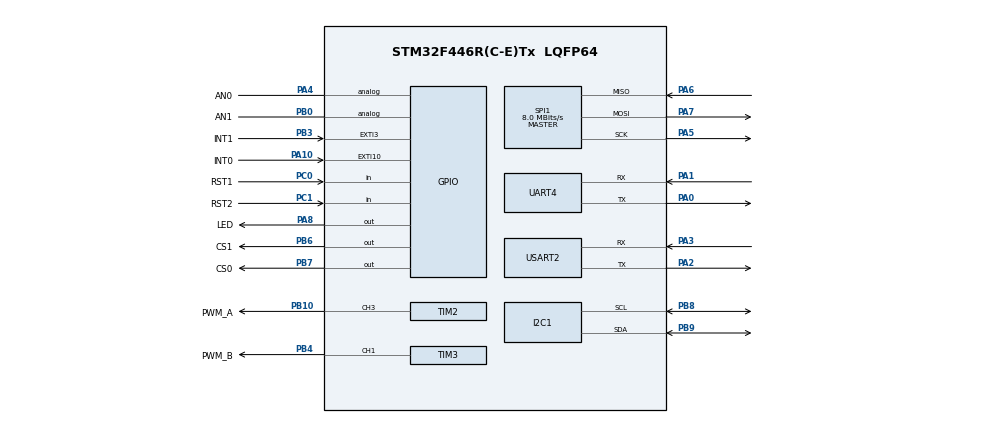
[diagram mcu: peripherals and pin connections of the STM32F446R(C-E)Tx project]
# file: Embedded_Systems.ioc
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Mcu.Family=STM32F4
Mcu.Name=STM32F446R(C-E)Tx
Mcu.Package=LQFP64
NVIC.I2C1_ER_IRQn=true\:0\:0\:false\:false\:true\:true\:true\:true
NVIC.I2C1_EV_IRQn=true\:0\:0\:false\:false\:true\:true\:true\:true
NVIC.PriorityGroup=NVIC_PRIORITYGROUP_4
NVIC.SPI1_IRQn=true\:0\:0\:false\:false\:true\:true\:true\:true
NVIC.UART4_IRQn=true\:0\:0\:false\:false\:true\:true\:true\:true
NVIC.USART2_IRQn=true\:0\:0\:false\:false\:true\:true\:true\:true
PA0-WKUP.Mode=Asynchronous
PA0-WKUP.Signal=UART4_TX
PA1.Mode=Asynchronous
PA1.Signal=UART4_RX
PA10.GPIO_Label=INT0
PA10.Signal=GPXTI10
PA2.Mode=Asynchronous
PA2.Signal=USART2_TX
PA3.Mode=Asynchronous
PA3.Signal=USART2_RX
PA4.GPIO_Label=AN0
PA4.Signal=GPIO_Analog
PA5.Mode=Full_Duplex_Master
PA5.Signal=SPI1_SCK
PA6.Mode=Full_Duplex_Master
PA6.Signal=SPI1_MISO
PA7.Mode=Full_Duplex_Master
PA7.Signal=SPI1_MOSI
PA8.GPIO_Label=LED
PA8.Signal=GPIO_Output
PB0.GPIO_Label=AN1
PB0.Signal=GPIO_Analog
PB10.GPIO_Label=PWM_A
PB10.Signal=S_TIM2_CH3
PB3.GPIO_Label=INT1
PB3.Signal=GPXTI3
PB4.GPIO_Label=PWM_B
PB4.Signal=S_TIM3_CH1
PB6.GPIO_Label=CS1
PB6.Signal=GPIO_Output
PB7.GPIO_Label=CS0
PB7.Signal=GPIO_Output
PB8.Mode=I2C
PB8.Signal=I2C1_SCL
PB9.Mode=I2C
PB9.Signal=I2C1_SDA
PC0.GPIO_Label=RST1
PC0.Signal=GPIO_Input
PC1.GPIO_Label=RST2
PC1.Signal=GPIO_Input
ProjectManager.HeapSize=0x200
ProjectManager.StackSize=0x400
ProjectManager.TargetToolchain=STM32CubeIDE
RCC.CortexFreq_Value=16000000
RCC.USBFreq_Value=96000000
RCC.VCOOutputFreq_Value=192000000
SH.S_TIM2_CH3.0=TIM2_CH3,PWM Generation3 CH3
SH.S_TIM3_CH1.0=TIM3_CH1,PWM Generation1 CH1
SPI1.CalculateBaudRate=8.0 MBits/s
SPI1.Direction=SPI_DIRECTION_2LINES
SPI1.Mode=SPI_MODE_MASTER
SPI1.VirtualType=VM_MASTER
TIM2.Channel-PWM\ Generation3\ CH3=TIM_CHANNEL_3
TIM3.Channel-PWM\ Generation1\ CH1=TIM_CHANNEL_1
UART4.VirtualMode=Asynchronous
USART2.VirtualMode=VM_ASYNC
board=custom

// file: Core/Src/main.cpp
/* USER CODE BEGIN Header */
/**
  ******************************************************************************
  * @file           : main.c
  * @brief          : Main program body
  ******************************************************************************
  * @attention
  *
  * Copyright (c) 2023 STMicroelectronics.
  * All rights reserved.
  *
  * This software is licensed under terms that can be found in the LICENSE file
  * in the root directory of this software component.
  * If no LICENSE file comes with this software, it is provided AS-IS.
  *
  ******************************************************************************
  */
/* USER CODE END Header */
#include "main.h"

I2C_HandleTypeDef hi2c1;

SPI_HandleTypeDef hspi1;

TIM_HandleTypeDef htim2;
TIM_HandleTypeDef htim3;

UART_HandleTypeDef huart4;

UART_HandleTypeDef huart2;

void SystemClock_Config(void);

static void MX_GPIO_Init(void);

static void MX_I2C1_Init(void);

static void MX_SPI1_Init(void);

static void MX_TIM2_Init(void);

static void MX_TIM3_Init(void);

static void MX_UART4_Init(void);

static void MX_USART2_UART_Init(void);

/* USER CODE BEGIN 0 */

// TODO 1
/**
 * Set the GPIO value to different values for an LED to turn on and off.
 *
 * The GPIO functionality for you to use can be found on line 233 of this file
 * EmbeddedSystems/Drivers/STM32F4xx_HAL_Driver/Inc/stm32f4xx_hal_gpio.h
 *
 *
 * NOTE: If you believe it to be stuck to on, realize that the device is running faster for you to process
 * You can use the HAL_Delay() function to delay the program for a certain amount of time
 */
void gpio_practice() {

}

// TODO 2
/**
 * Sending a message to your computer through the UART
 *
 * The UART functionality for you to use can be found on line 721 of this file
 * EmbeddedSystems/Drivers/STM32F4xx_HAL_Driver/Inc/stm32f4xx_hal_uart.h
 */
void uart_practice(const char* message, size_t len) {
}

// TODO 3
/**
 * You will read the value of the I2C device and print it to the UART
 *
 * The I2C functionality for you to use can be found on line 564 of this file
 * EmbeddedSystems/Drivers/STM32F4xx_HAL_Driver/Inc/stm32f4xx_hal_i2c.h
 *
 * Find the values to read in this datasheet:
 *
 */
void i2c_practice() {

}

// TODO 4
/**
 * Grab the value of the SPI device and print it to the UART
 * You will need to set the CS pin to low, read the value, and set the CS pin to high
 * after you are done reading
 *
 * The SPI functionality for you to use can be found on line 669 of this file
 * EmbeddedSystems/Drivers/STM32F4xx_HAL_Driver/Inc/stm32f4xx_hal_spi.h
 *
 * Read the datasheet to find the values to read:
 *
 */
void spi_practice() {
}

/* USER CODE END 0 */

int main(void) {

    /* MCU Configuration--------------------------------------------------------*/

    /* Reset of all peripherals, Initializes the Flash interface and the Systick. */
    HAL_Init();

    /* Configure the system clock */
    SystemClock_Config();

    /* Initialize all configured peripherals */
    MX_GPIO_Init();
    MX_I2C1_Init();
    MX_SPI1_Init();
    MX_TIM2_Init();
    MX_TIM3_Init();
    MX_UART4_Init();
    MX_USART2_UART_Init();

    /* Infinite loop */
    /* USER CODE BEGIN WHILE */

    while (1) {
        gpio_practice();
        uart_practice();
        i2c_practice();
        spi_practice();
        /* USER CODE END WHILE */

    }
}

void SystemClock_Config(void) {
    RCC_OscInitTypeDef RCC_OscInitStruct = {0};
    RCC_ClkInitTypeDef RCC_ClkInitStruct = {0};

    /** Configure the main internal regulator output voltage
    */
    __HAL_RCC_PWR_CLK_ENABLE();
    __HAL_PWR_VOLTAGESCALING_CONFIG(PWR_REGULATOR_VOLTAGE_SCALE3);

    /** Initializes the RCC Oscillators according to the specified parameters
    * in the RCC_OscInitTypeDef structure.
    */
    RCC_OscInitStruct.OscillatorType = RCC_OSCILLATORTYPE_HSI;
    RCC_OscInitStruct.HSIState = RCC_HSI_ON;
    RCC_OscInitStruct.HSICalibrationValue = RCC_HSICALIBRATION_DEFAULT;
    RCC_OscInitStruct.PLL.PLLState = RCC_PLL_NONE;
    if (HAL_RCC_OscConfig(&RCC_OscInitStruct) != HAL_OK) {
        Error_Handler();
    }

    /** Initializes the CPU, AHB and APB buses clocks
    */
    RCC_ClkInitStruct.ClockType = RCC_CLOCKTYPE_HCLK | RCC_CLOCKTYPE_SYSCLK
                                  | RCC_CLOCKTYPE_PCLK1 | RCC_CLOCKTYPE_PCLK2;
    RCC_ClkInitStruct.SYSCLKSource = RCC_SYSCLKSOURCE_HSI;
    RCC_ClkInitStruct.AHBCLKDivider = RCC_SYSCLK_DIV1;
    RCC_ClkInitStruct.APB1CLKDivider = RCC_HCLK_DIV1;
    RCC_ClkInitStruct.APB2CLKDivider = RCC_HCLK_DIV1;

    if (HAL_RCC_ClockConfig(&RCC_ClkInitStruct, FLASH_LATENCY_0) != HAL_OK) {
        Error_Handler();
    }
}

static void MX_I2C1_Init(void) {

    hi2c1.Instance = I2C1;
    hi2c1.Init.ClockSpeed = 100000;
    hi2c1.Init.DutyCycle = I2C_DUTYCYCLE_2;
    hi2c1.Init.OwnAddress1 = 0;
    hi2c1.Init.AddressingMode = I2C_ADDRESSINGMODE_7BIT;
    hi2c1.Init.DualAddressMode = I2C_DUALADDRESS_DISABLE;
    hi2c1.Init.OwnAddress2 = 0;
    hi2c1.Init.GeneralCallMode = I2C_GENERALCALL_DISABLE;
    hi2c1.Init.NoStretchMode = I2C_NOSTRETCH_DISABLE;
    if (HAL_I2C_Init(&hi2c1) != HAL_OK) {
        Error_Handler();
    }

}

static void MX_SPI1_Init(void) {

    /* SPI1 parameter configuration*/
    hspi1.Instance = SPI1;
    hspi1.Init.Mode = SPI_MODE_MASTER;
    hspi1.Init.Direction = SPI_DIRECTION_2LINES;
    hspi1.Init.DataSize = SPI_DATASIZE_8BIT;
    hspi1.Init.CLKPolarity = SPI_POLARITY_LOW;
    hspi1.Init.CLKPhase = SPI_PHASE_1EDGE;
    hspi1.Init.NSS = SPI_NSS_SOFT;
    hspi1.Init.BaudRatePrescaler = SPI_BAUDRATEPRESCALER_2;
    hspi1.Init.FirstBit = SPI_FIRSTBIT_MSB;
    hspi1.Init.TIMode = SPI_TIMODE_DISABLE;
    hspi1.Init.CRCCalculation = SPI_CRCCALCULATION_DISABLE;
    hspi1.Init.CRCPolynomial = 10;
    if (HAL_SPI_Init(&hspi1) != HAL_OK) {
        Error_Handler();
    }

}

static void MX_TIM2_Init(void) {

    TIM_MasterConfigTypeDef sMasterConfig = {0};
    TIM_OC_InitTypeDef sConfigOC = {0};

    htim2.Instance = TIM2;
    htim2.Init.Prescaler = 0;
    htim2.Init.CounterMode = TIM_COUNTERMODE_UP;
    htim2.Init.Period = 4294967295;
    htim2.Init.ClockDivision = TIM_CLOCKDIVISION_DIV1;
    htim2.Init.AutoReloadPreload = TIM_AUTORELOAD_PRELOAD_DISABLE;
    if (HAL_TIM_PWM_Init(&htim2) != HAL_OK) {
        Error_Handler();
    }
    sMasterConfig.MasterOutputTrigger = TIM_TRGO_RESET;
    sMasterConfig.MasterSlaveMode = TIM_MASTERSLAVEMODE_DISABLE;
    if (HAL_TIMEx_MasterConfigSynchronization(&htim2, &sMasterConfig) != HAL_OK) {
        Error_Handler();
    }
    sConfigOC.OCMode = TIM_OCMODE_PWM1;
    sConfigOC.Pulse = 0;
    sConfigOC.OCPolarity = TIM_OCPOLARITY_HIGH;
    sConfigOC.OCFastMode = TIM_OCFAST_DISABLE;
    if (HAL_TIM_PWM_ConfigChannel(&htim2, &sConfigOC, TIM_CHANNEL_3) != HAL_OK) {
        Error_Handler();
    }
    HAL_TIM_MspPostInit(&htim2);

}

static void MX_TIM3_Init(void) {

    TIM_MasterConfigTypeDef sMasterConfig = {0};
    TIM_OC_InitTypeDef sConfigOC = {0};

    htim3.Instance = TIM3;
    htim3.Init.Prescaler = 0;
    htim3.Init.CounterMode = TIM_COUNTERMODE_UP;
    htim3.Init.Period = 65535;
    htim3.Init.ClockDivision = TIM_CLOCKDIVISION_DIV1;
    htim3.Init.AutoReloadPreload = TIM_AUTORELOAD_PRELOAD_DISABLE;
    if (HAL_TIM_PWM_Init(&htim3) != HAL_OK) {
        Error_Handler();
    }
    sMasterConfig.MasterOutputTrigger = TIM_TRGO_RESET;
    sMasterConfig.MasterSlaveMode = TIM_MASTERSLAVEMODE_DISABLE;
    if (HAL_TIMEx_MasterConfigSynchronization(&htim3, &sMasterConfig) != HAL_OK) {
        Error_Handler();
    }
    sConfigOC.OCMode = TIM_OCMODE_PWM1;
    sConfigOC.Pulse = 0;
    sConfigOC.OCPolarity = TIM_OCPOLARITY_HIGH;
    sConfigOC.OCFastMode = TIM_OCFAST_DISABLE;
    if (HAL_TIM_PWM_ConfigChannel(&htim3, &sConfigOC, TIM_CHANNEL_1) != HAL_OK) {
        Error_Handler();
    }
    HAL_TIM_MspPostInit(&htim3);

}

static void MX_UART4_Init(void) {

    huart4.Instance = UART4;
    huart4.Init.BaudRate = 115200;
    huart4.Init.WordLength = UART_WORDLENGTH_8B;
    huart4.Init.StopBits = UART_STOPBITS_1;
    huart4.Init.Parity = UART_PARITY_NONE;
    huart4.Init.Mode = UART_MODE_TX_RX;
    huart4.Init.HwFlowCtl = UART_HWCONTROL_NONE;
    huart4.Init.OverSampling = UART_OVERSAMPLING_16;
    if (HAL_UART_Init(&huart4) != HAL_OK) {
        Error_Handler();
    }

}

static void MX_USART2_UART_Init(void) {

    huart2.Instance = USART2;
    huart2.Init.BaudRate = 115200;
    huart2.Init.WordLength = UART_WORDLENGTH_8B;
    huart2.Init.StopBits = UART_STOPBITS_1;
    huart2.Init.Parity = UART_PARITY_NONE;
    huart2.Init.Mode = UART_MODE_TX_RX;
    huart2.Init.HwFlowCtl = UART_HWCONTROL_NONE;
    huart2.Init.OverSampling = UART_OVERSAMPLING_16;
    if (HAL_UART_Init(&huart2) != HAL_OK) {
        Error_Handler();
    }

}

static void MX_GPIO_Init(void) {
    GPIO_InitTypeDef GPIO_InitStruct = {0};

    /* GPIO Ports Clock Enable */
    __HAL_RCC_GPIOC_CLK_ENABLE();
    __HAL_RCC_GPIOA_CLK_ENABLE();
    __HAL_RCC_GPIOB_CLK_ENABLE();

    /*Configure GPIO pin Output Level */
    HAL_GPIO_WritePin(LED_GPIO_Port, LED_Pin, GPIO_PIN_RESET);

    /*Configure GPIO pin Output Level */
    HAL_GPIO_WritePin(GPIOB, CS1_Pin | CS0_Pin, GPIO_PIN_RESET);

    /*Configure GPIO pins : RST1_Pin RST2_Pin */
    GPIO_InitStruct.Pin = RST1_Pin | RST2_Pin;
    GPIO_InitStruct.Mode = GPIO_MODE_INPUT;
    GPIO_InitStruct.Pull = GPIO_NOPULL;
    HAL_GPIO_Init(GPIOC, &GPIO_InitStruct);

    /*Configure GPIO pin : AN0_Pin */
    GPIO_InitStruct.Pin = AN0_Pin;
    GPIO_InitStruct.Mode = GPIO_MODE_ANALOG;
    GPIO_InitStruct.Pull = GPIO_NOPULL;
    HAL_GPIO_Init(AN0_GPIO_Port, &GPIO_InitStruct);

    /*Configure GPIO pin : AN1_Pin */
    GPIO_InitStruct.Pin = AN1_Pin;
    GPIO_InitStruct.Mode = GPIO_MODE_ANALOG;
    GPIO_InitStruct.Pull = GPIO_NOPULL;
    HAL_GPIO_Init(AN1_GPIO_Port, &GPIO_InitStruct);

    /*Configure GPIO pin : LED_Pin */
    GPIO_InitStruct.Pin = LED_Pin;
    GPIO_InitStruct.Mode = GPIO_MODE_OUTPUT_PP;
    GPIO_InitStruct.Pull = GPIO_NOPULL;
    GPIO_InitStruct.Speed = GPIO_SPEED_FREQ_LOW;
    HAL_GPIO_Init(LED_GPIO_Port, &GPIO_InitStruct);

    /*Configure GPIO pin : INT0_Pin */
    GPIO_InitStruct.Pin = INT0_Pin;
    GPIO_InitStruct.Mode = GPIO_MODE_IT_RISING;
    GPIO_InitStruct.Pull = GPIO_NOPULL;
    HAL_GPIO_Init(INT0_GPIO_Port, &GPIO_InitStruct);

    /*Configure GPIO pin : INT1_Pin */
    GPIO_InitStruct.Pin = INT1_Pin;
    GPIO_InitStruct.Mode = GPIO_MODE_IT_RISING;
    GPIO_InitStruct.Pull = GPIO_NOPULL;
    HAL_GPIO_Init(INT1_GPIO_Port, &GPIO_InitStruct);

    /*Configure GPIO pins : CS1_Pin CS0_Pin */
    GPIO_InitStruct.Pin = CS1_Pin | CS0_Pin;
    GPIO_InitStruct.Mode = GPIO_MODE_OUTPUT_PP;
    GPIO_InitStruct.Pull = GPIO_NOPULL;
    GPIO_InitStruct.Speed = GPIO_SPEED_FREQ_LOW;
    HAL_GPIO_Init(GPIOB, &GPIO_InitStruct);

}

void Error_Handler(void) {
    __disable_irq();
    while (1) {
    }
}
